# CC27x0 register map
File version: 1.0
CPU: CM4 r0p4, little endian, no MPU, no FPU, VTOR, 3 interrupt priority bits
Registers are 32-bit, read-write, reset 0x0 unless marked. A register's access mark holds for its fields unless they carry their own. Offsets are from the block's base; [hi:lo] are bit positions; {n}, {i} and the like mark numbered series; 'fields as' and 'values as' point back to an identical list.

## GPIO — MCU GPIO - I/F for controlling and reading IO status and IO event status
Base 0x40023000
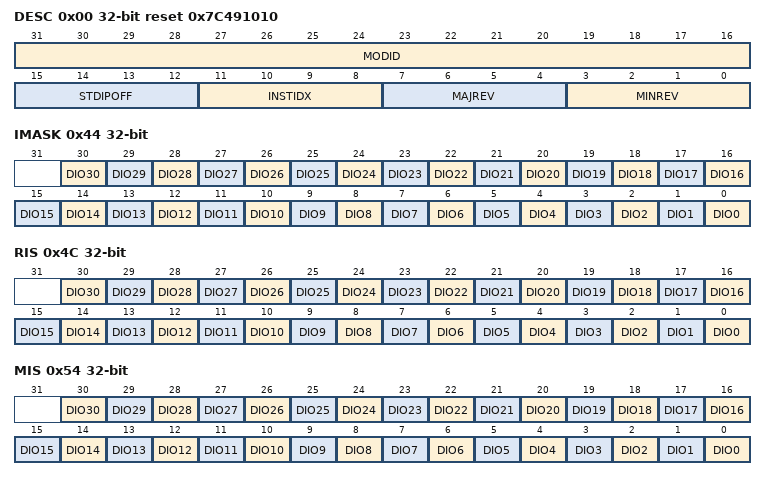
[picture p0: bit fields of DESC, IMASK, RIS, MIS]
0x00 DESC ro reset 0x7C491010 — Description Register. This register provides IP module ID, revision information, instance index and standard MMR registers offset.
  [31:16] MODID — Module identifier used to uniquely identify this IP.
  [15:12] STDIPOFF — Standard IP MMR block offset. Standard IP MMRs are the set from aggregated IRQ registers till DTB. 0: Standard IP MMRs do not exist 0x1-0xF: Standard IP MMRs begin at offset of (64*STDIPOFF from the base IP address)
  [11:8] INSTIDX — IP Instance ID number. If multiple instances of IP exist in the device, this field can identify the instance number (0-15).
  [7:4] MAJREV — Major revision of IP (0-15).
  [3:0] MINREV — Minor revision of IP (0-15).
0x04 DESCEX ro reset 0x1E — Provide IP-specific instance information
  [5:0] NUMDIO — This provides the total number of DIOs supported by GPIO. The number of DIOs supprted is NUMDIO + 1
0x44 IMASK — Interrupt mask for DIO pins
  [all] fields
    1=SET (Set Interrrupt Mask); 0=CLR (Clear Interrupt Mask)
  [n] DIO{n} (n=0..30) — Interrupt mask for DIO{n}
0x4C RIS ro — Raw interrupt flag for DIO pins
  [all] fields
    1=SET (Interrupt occured); 0=CLR (Interrupt did not occur)
  [n] DIO{n} (n=0..30) — Raw interrupt flag for DIO{n}
0x54 MIS ro — Masked interrupt flag for DIO pins
  [all] fields
    1=SET (Interrupt occured); 0=CLR (Interrupt did not occur)
  [n] DIO{n} (n=0..30) — Masked interrupt flag for DIO{n}
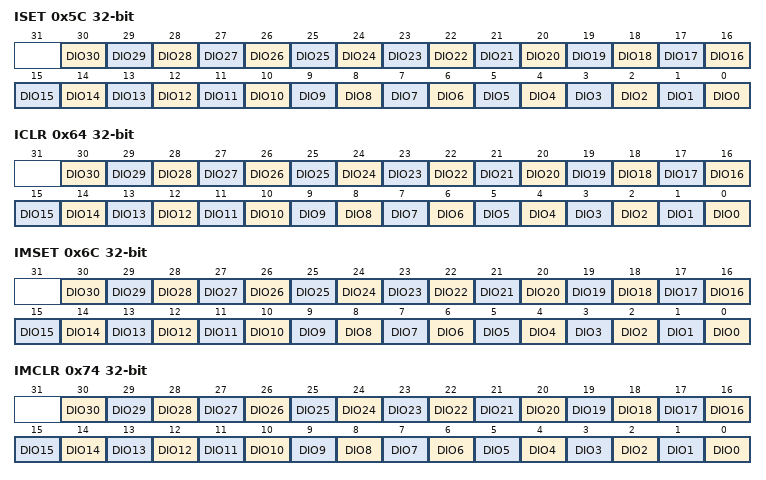
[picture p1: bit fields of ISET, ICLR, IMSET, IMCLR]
0x5C ISET wo — Set interrupt flag in RIS by writing a one
  [all] fields
    1=SET (Set Interrupt); 0=NOEFF (Writing 0 has no effect)
  [n] DIO{n} (n=0..30) — Set DIO{n} in RIS
0x64 ICLR wo — Clear interrupt flag in RIS by writing a one
  [all] fields
    1=CLR (Clear Interrupt); 0=NOEFF (Writing 0 has no effect)
  [n] DIO{n} (n=0..30) — Clears DIO{n} in RIS
0x6C IMSET wo — Set interrupt mask in IMASK by writing a one
  [all] fields
    1=SET (Set interrupt mask); 0=NOEFF (Writing 0 has no effect)
  [n] DIO{n} (n=0..30) — Sets DIO{n} in IMASK
0x74 IMCLR wo — Clear interrupt mask in IMASK by writing a one
  [all] fields
    1=CLR (Clear interrupt mask); 0=NOEFF (Writing 0 has no effect)
  [n] DIO{n} (n=0..30) — Clears DIO{n} in IMASK
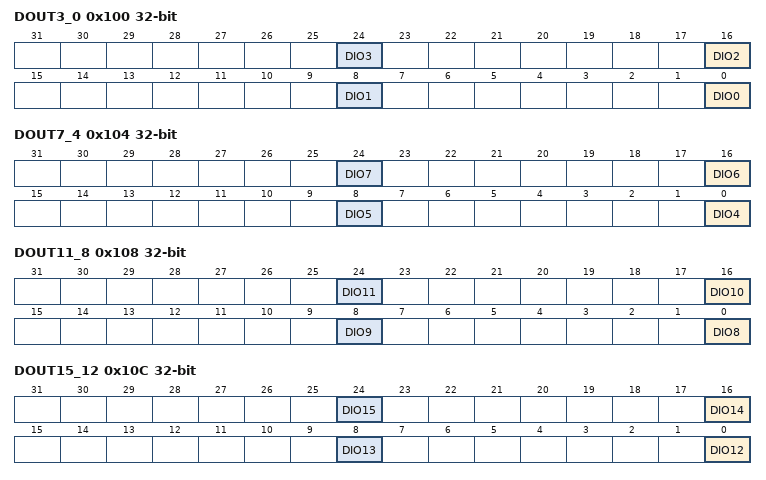
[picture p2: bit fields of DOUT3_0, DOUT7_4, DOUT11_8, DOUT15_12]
0x100 DOUT3_0 — Alias register for byte access to DOUT31_0[3:0] bits.
  [all] fields
    1=ONE (Output is set to 1); 0=ZERO (Output is set to 0)
  [8n] DIO{n} (n=0..3) — Data output for DIO{n}
0x104 DOUT7_4 — Alias register for byte access to DOUT31_0[7:4] bits
  [all] fields
    1=ONE (Output is set to 1); 0=ZERO (Output is set to 0)
  [8n-32] DIO{n} (n=4..7) — Data output for DIO{n}
0x108 DOUT11_8 — Alias register for byte access to DOUT31_0[11:8] bits
  [all] fields
    1=ONE (Output is set to 1); 0=ZERO (Output is set to 0)
  [8n-64] DIO{n} (n=8..11) — Data output for DIO{n}
0x10C DOUT15_12 — Alias register for byte access to DOUT31_0[15:12] bits
  [all] fields
    1=ONE (Output is set to 1); 0=ZERO (Output is set to 0)
  [8n-96] DIO{n} (n=12..15) — Data output for DIO{n}
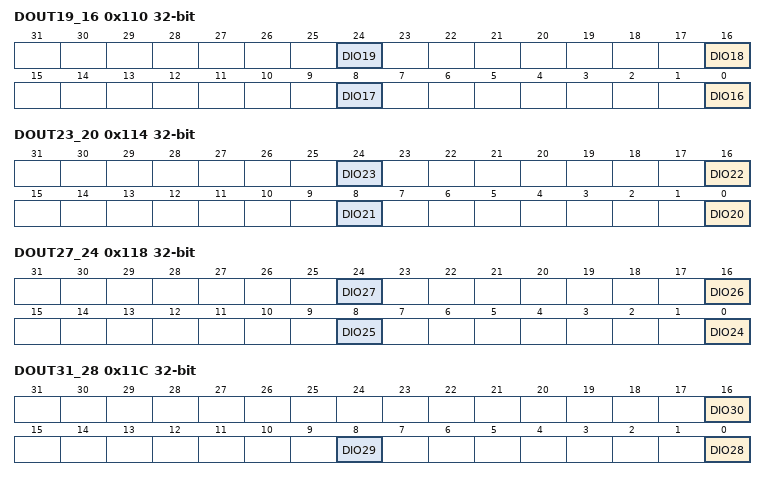
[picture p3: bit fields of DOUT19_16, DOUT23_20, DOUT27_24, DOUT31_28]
0x110 DOUT19_16 — Alias register for byte access to DOUT31_0[19:16] bits
  [all] fields
    1=ONE (Output is set to 1); 0=ZERO (Output is set to 0)
  [8n-128] DIO{n} (n=16..19) — Data output for DIO{n}
0x114 DOUT23_20 — Alias register for byte access to DOUT31_0[23:20] bits
  [all] fields
    1=ONE (Output is set to 1); 0=ZERO (Output is set to 0)
  [8n-160] DIO{n} (n=20..23) — Data output for DIO{n}
0x118 DOUT27_24 — Alias register for byte access to DOUT31_0[27:24] bits
  [all] fields
    1=ONE (Output is set to 1); 0=ZERO (Output is set to 0)
  [8n-192] DIO{n} (n=24..27) — Data output for DIO{n}
0x11C DOUT31_28 — Alias register for byte access to DOUT31_0[31:28] bits
  [all] fields
    1=ONE (Output is set to 1); 0=ZERO (Output is set to 0)
  [16] DIO30 — Data output for DIO30
  [8] DIO29 — Data output for DIO29
  [0] DIO28 — Data output for DIO28
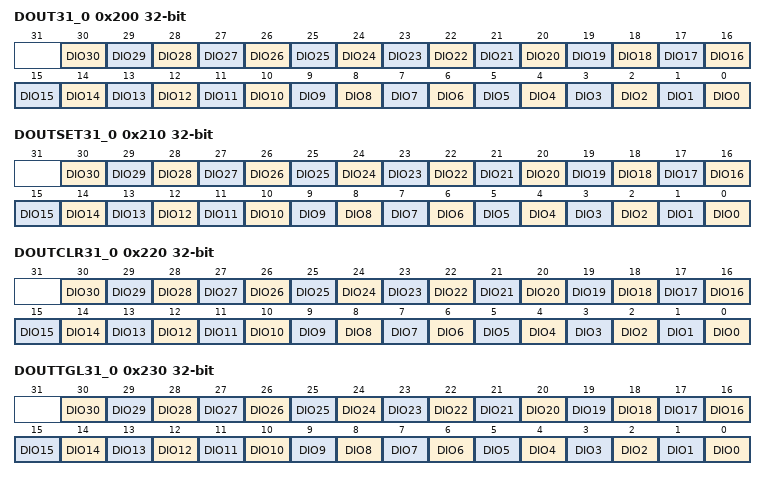
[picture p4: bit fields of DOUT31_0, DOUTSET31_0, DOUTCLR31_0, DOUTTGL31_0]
0x200 DOUT31_0 — Data Output for DIO 31 to 0 pins.
  [all] fields
    1=ONE (Output is set to 1); 0=ZERO (Output is set to 0)
  [n] DIO{n} (n=0..30) — Data output for DIO{n}
0x210 DOUTSET31_0 wo — Alias regiser to set the corresponding bits of DOUT31_0 register.
  [all] fields
    1=SET; 0=NOEFF (No effect)
  [n] DIO{n} (n=0..30) — Set bit DOUT31_0.DIO{n}
0x220 DOUTCLR31_0 wo — Alias regiser to clear the corresponding bits of DOUT31_0 register.
  [all] fields
    1=CLR (Clear); 0=NOEFF (No effect)
  [n] DIO{n} (n=0..30) — Clear bit DOUT31_0.DIO{n}
0x230 DOUTTGL31_0 wo — Alias regiser to toggle the corresponding bits of DOUT31_0 register.
  [all] fields
    1=TOGGLE; 0=NOEFF (No effect)
  [n] DIO{n} (n=0..30) — Toggles bit DOUT31_0.DIO{n}
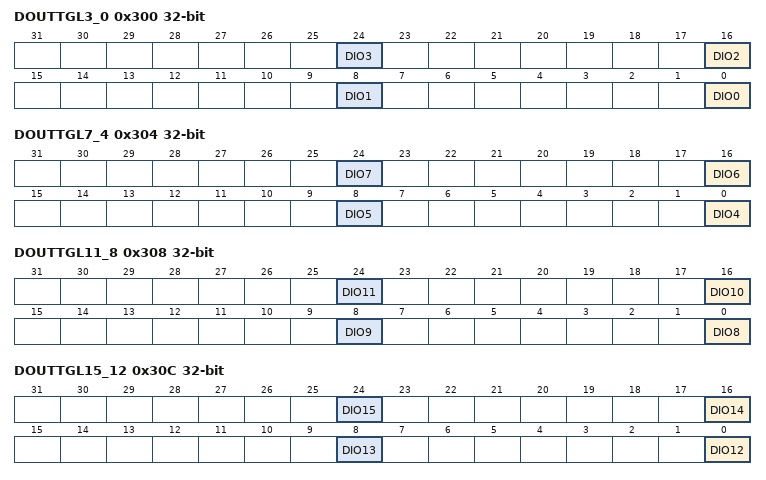
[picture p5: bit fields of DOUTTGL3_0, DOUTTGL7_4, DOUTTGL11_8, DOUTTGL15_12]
0x300 DOUTTGL3_0 wo — Alias regiser to toggle the corresponding bits of DOUT31_0[3:0] register.
  [all] fields
    1=TOGGLE; 0=NOEFF (No effect)
  [8n] DIO{n} (n=0..3) — Toggles bit DOUT31_0.DIO{n}
0x304 DOUTTGL7_4 wo — Alias regiser to toggle the corresponding bits of DOUT31_0[7:4] register.
  [all] fields
    1=TOGGLE; 0=NOEFF (No effect)
  [8n-32] DIO{n} (n=4..7) — Toggles bit DOUT31_0.DIO{n}
0x308 DOUTTGL11_8 wo — Alias regiser to toggle the corresponding bits of DOUT31_0[11:8] register.
  [all] fields
    1=TOGGLE; 0=NOEFF (No effect)
  [8n-64] DIO{n} (n=8..11) — Toggles bit DOUT31_0.DIO{n}
0x30C DOUTTGL15_12 wo — Alias regiser to toggle the corresponding bits of DOUT31_0[15:12] register.
  [all] fields
    1=TOGGLE; 0=NOEFF (No effect)
  [8n-96] DIO{n} (n=12..15) — Toggles bit DOUT31_0.DIO{n}
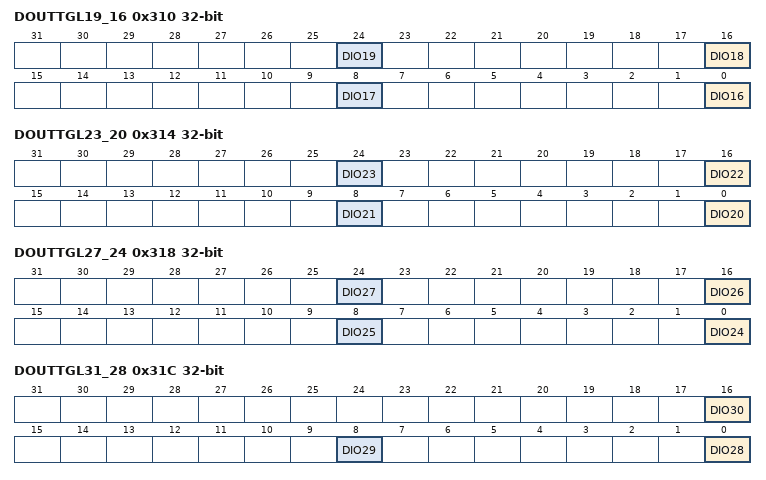
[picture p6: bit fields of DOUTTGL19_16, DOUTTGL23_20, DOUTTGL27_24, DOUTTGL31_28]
0x310 DOUTTGL19_16 wo — Alias regiser to toggle the corresponding bits of DOUT31_0[19:16] register.
  [all] fields
    1=TOGGLE; 0=NOEFF (No effect)
  [8n-128] DIO{n} (n=16..19) — Toggles bit DOUT31_0.DIO{n}
0x314 DOUTTGL23_20 wo — Alias regiser to toggle the corresponding bits of DOUT31_0[23:20] register.
  [all] fields
    1=TOGGLE; 0=NOEFF (No effect)
  [8n-160] DIO{n} (n=20..23) — Toggles bit DOUT31_0.DIO{n}
0x318 DOUTTGL27_24 wo — Alias regiser to toggle the corresponding bits of DOUT31_0[27:24] register.
  [all] fields
    1=TOGGLE; 0=NOEFF (No effect)
  [8n-192] DIO{n} (n=24..27) — Toggles bit DOUT31_0.DIO{n}
0x31C DOUTTGL31_28 wo — Alias regiser to toggle the corresponding bits of DOUT31_0[31:28] register.
  [all] fields
    1=TOGGLE; 0=NOEFF (No effect)
  [16] DIO30 — Toggles bit DOUT31_0.DIO30
  [8] DIO29 — Toggles bit DOUT31_0.DIO29
  [0] DIO28 — Toggles bit DOUT31_0.DIO28
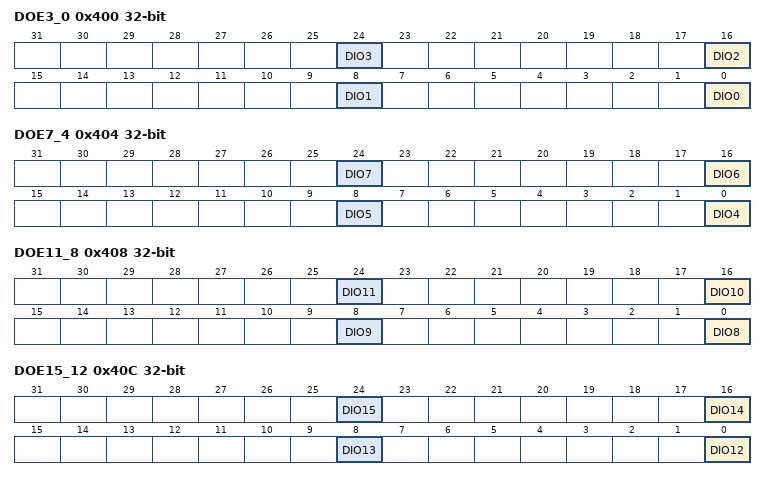
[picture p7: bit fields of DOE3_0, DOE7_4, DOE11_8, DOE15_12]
0x400 DOE3_0 — Alias register for byte access to DOE31_0[3:0] bits.
  [all] fields
    1=EN (Output enabled); 0=DIS (Output disabled)
  [8n] DIO{n} (n=0..3) — Data output enable for DIO{n}
0x404 DOE7_4 — Alias register for byte access to DOE31_0[7:4] bits.
  [all] fields
    1=EN (Output enabled); 0=DIS (Output disabled)
  [8n-32] DIO{n} (n=4..7) — Data output enable for DIO{n}
0x408 DOE11_8 — Alias register for byte access to DOE31_0[11:8] bits.
  [all] fields
    1=EN (Output enabled); 0=DIS (Output disabled)
  [8n-64] DIO{n} (n=8..11) — Data output enable for DIO{n}
0x40C DOE15_12 — Alias register for byte access to DOE31_0[15:12] bits.
  [all] fields
    1=EN (Output enabled); 0=DIS (Output disabled)
  [8n-96] DIO{n} (n=12..15) — Data output enable for DIO{n}
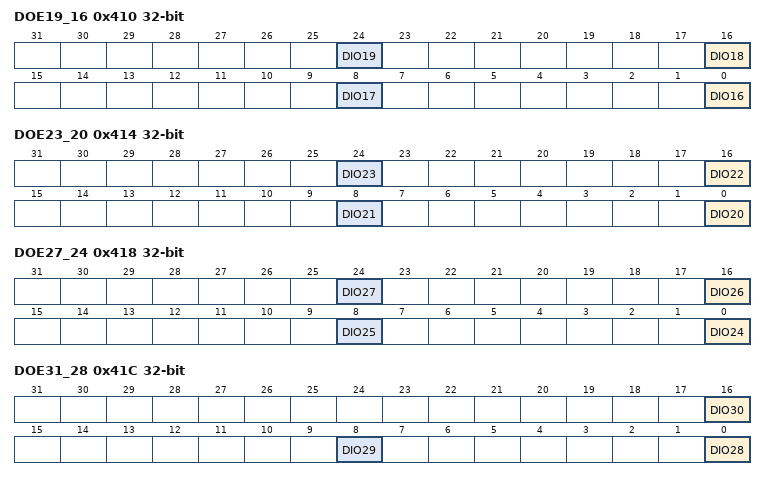
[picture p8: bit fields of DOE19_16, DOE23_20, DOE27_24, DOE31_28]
0x410 DOE19_16 — Alias register for byte access to DOE31_0[19:16] bits.
  [all] fields
    1=EN (Output enabled); 0=DIS (Output disabled)
  [8n-128] DIO{n} (n=16..19) — Data output enable for DIO{n}
0x414 DOE23_20 — Alias register for byte access to DOE31_0[23:20] bits.
  [all] fields
    1=EN (Output enabled); 0=DIS (Output disabled)
  [8n-160] DIO{n} (n=20..23) — Data output enable for DIO{n}
0x418 DOE27_24 — Alias register for byte access to DOE31_0[24:27] bits.
  [all] fields
    1=EN (Output enabled); 0=DIS (Output disabled)
  [8n-192] DIO{n} (n=24..27) — Data output enable for DIO{n}
0x41C DOE31_28 — Alias register for byte access to DOE31_0[31:28] bits.
  [all] fields
    1=EN (Output enabled); 0=DIS (Output disabled)
  [16] DIO30 — Data output enable for DIO30
  [8] DIO29 — Data output enable for DIO29
  [0] DIO28 — Data output enable for DIO28
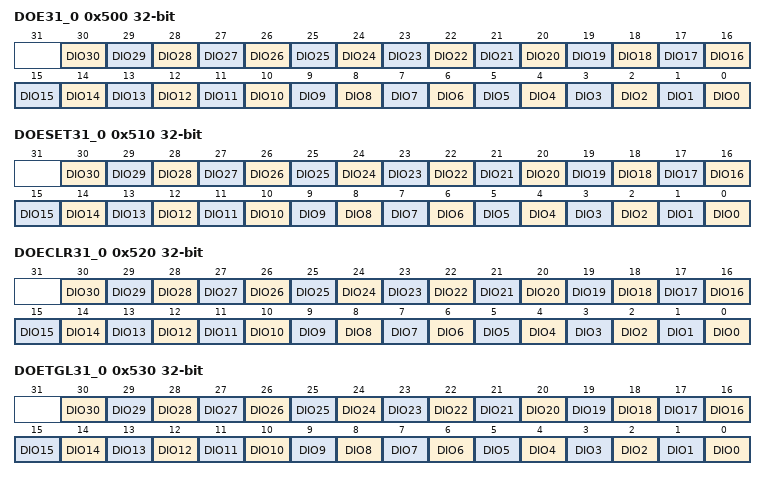
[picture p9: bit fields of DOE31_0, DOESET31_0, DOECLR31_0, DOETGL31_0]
0x500 DOE31_0 — Data output enable for DIO 31 to 0 pins.
  [all] fields
    1=EN (Output enabled); 0=DIS (Output disabled)
  [n] DIO{n} (n=0..30) — Data output enable for DIO{n}
0x510 DOESET31_0 wo — Alias regiser to set the corresponding bits of DOE31_0 register.
  [all] fields
    1=SET; 0=NOEFF (No effect)
  [n] DIO{n} (n=0..30) — Sets bit DOE31_0.DIO{n}
0x520 DOECLR31_0 wo — Alias regiser to clear the corresponding bits of DOE31_0 register.
  [all] fields
    1=CLR (Clear); 0=NOEFF (No effect)
  [n] DIO{n} (n=0..30) — Clears bit DOE31_0.DIO{n}
0x530 DOETGL31_0 wo — Alias regiser to toggle the corresponding bits of DOE31_0 register.
  [all] fields
    1=TOGGLE; 0=NOEFF (No effect)
  [n] DIO{n} (n=0..30) — Toggles bit DOE31_0.DIO{n}
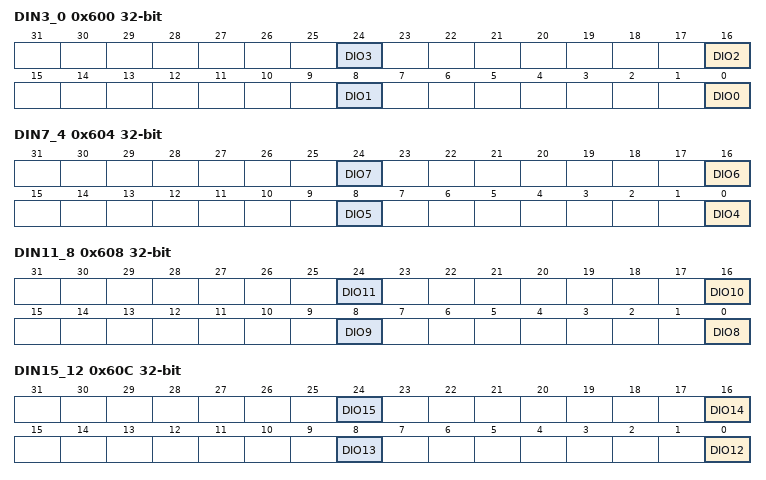
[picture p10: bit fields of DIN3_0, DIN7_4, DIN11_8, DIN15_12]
0x600 DIN3_0 ro — Alias register for byte access to DIN31_0[3:0] bits.
  [all] fields
    1=ONE (Input value is 1); 0=ZERO (Input value is 0)
  [8n] DIO{n} (n=0..3) — Data input from DIO{n}
0x604 DIN7_4 ro — Alias register for byte access to DIN31_0[7:4] bits.
  [all] fields
    1=ONE (Input value is 1); 0=ZERO (Input value is 0)
  [8n-32] DIO{n} (n=4..7) — Data input from DIO{n}
0x608 DIN11_8 ro — Alias register for byte access to DIN31_0[11:8] bits.
  [all] fields
    1=ONE (Input value is 1); 0=ZERO (Input value is 0)
  [8n-64] DIO{n} (n=8..11) — Data input from DIO{n}
0x60C DIN15_12 ro — Alias register for byte access to DIN31_0[15:12] bits.
  [all] fields
    1=ONE (Input value is 1); 0=ZERO (Input value is 0)
  [8n-96] DIO{n} (n=12..15) — Data input from DIO{n}
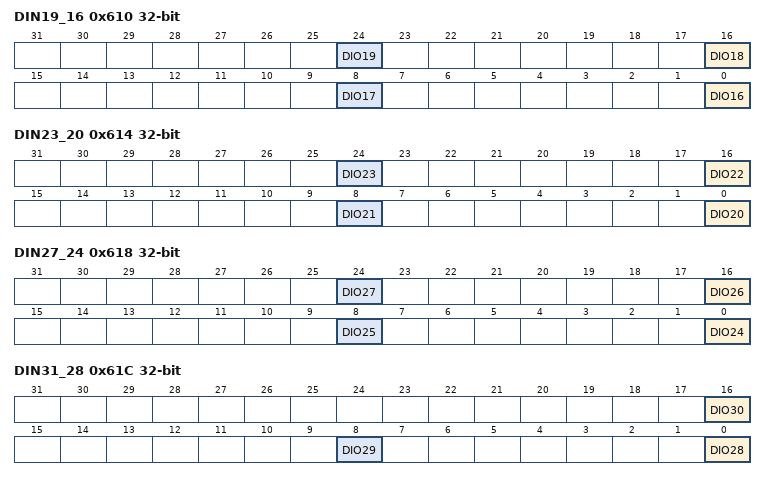
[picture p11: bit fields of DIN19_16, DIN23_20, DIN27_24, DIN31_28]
0x610 DIN19_16 ro — Alias register for byte access to DIN31_0[19:16] bits.
  [all] fields
    1=ONE (Input value is 1); 0=ZERO (Input value is 0)
  [8n-128] DIO{n} (n=16..19) — Data input from DIO{n}
0x614 DIN23_20 ro — Alias register for byte access to DIN31_0[23:20] bits.
  [all] fields
    1=ONE (Input value is 1); 0=ZERO (Input value is 0)
  [8n-160] DIO{n} (n=20..23) — Data input from DIO{n}
0x618 DIN27_24 ro — Alias register for byte access to DIN31_0[24:27] bits.
  [all] fields
    1=ONE (Input value is 1); 0=ZERO (Input value is 0)
  [8n-192] DIO{n} (n=24..27) — Data input from DIO{n}
0x61C DIN31_28 ro — Alias register for byte access to DIN31_0[31:28] bits.
  [all] fields
    1=ONE (Input value is 1); 0=ZERO (Input value is 0)
  [16] DIO30 — Data input from DIO30
  [8] DIO29 — Data input from DIO29
  [0] DIO28 — Data input from DIO28
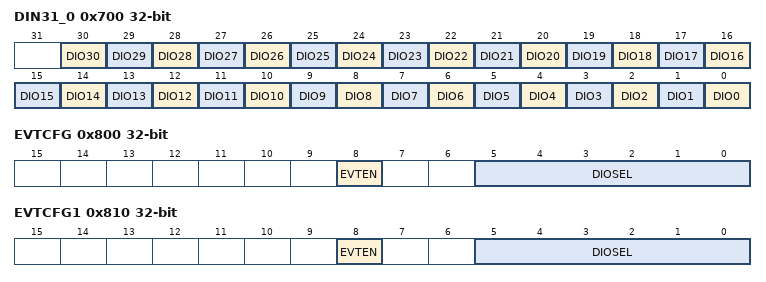
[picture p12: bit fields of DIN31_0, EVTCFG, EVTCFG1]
0x700 DIN31_0 ro — Data input from DIO 31 to 0 pins.
  [all] fields
    1=ONE (Input value is 1); 0=ZERO (Input value is 0)
  [n] DIO{n} (n=0..30) — Data input from DIO{n}
0x800 EVTCFG — Event configuration 0. This register is used to select DIO for GPIO to publish event on SVT event fabric. It also contains enable bit that is used to mask the event.
  [8] EVTEN — Enables GPIO to publish edge qualified selected DIO event on SVT event fabric. Design note: The edge detector flop is cleared automatically for the selected DIO once the event is published.
    1=EN (Enable); 0=DIS (Disable)
  [5:0] DIOSEL — This is used to select DIO for event generation. For example, DIOSEL = 0x0 selects DIO0 and DIOSEL = 0x8 selects DIO8.
    63=MAXIMUM (Maximum value); 0=MINIMUM (Minimum value)
0x810 EVTCFG1 — Event configuration 1. This register is used to select DIO for GPIO to publish event on SVT event fabric. It also contains enable bit that is used to mask the event.
  fields as EVTCFG
